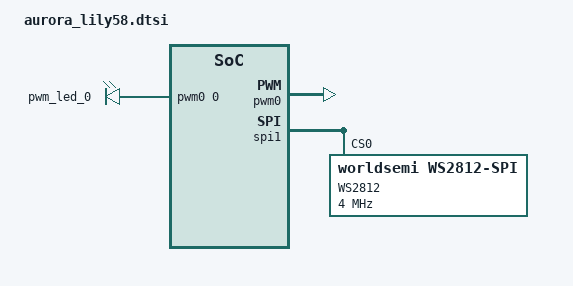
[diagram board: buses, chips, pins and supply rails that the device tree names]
/ {
    chosen {
        zmk,backlight,underglow = &backlight;
    };
};

&pwm0 {
    status = "okay";
};

&backlight {
    compatible = "pwm-leds";
    pwm_led_0 {
        pwms = <&pwm0 0 PWM_MSEC(20) PWM_POLARITY_NORMAL>;
    };
};

&spi1 {
    led_strip: ws2812@0 {
        compatible = "worldsemi,ws2812-spi";
        label = "WS2812";

        /* SPI */
        reg = <0>;
        spi-max-frequency = <4000000>;

        /* WS2812 */
        chain-length = <10>; /* number of LEDs */
        spi-one-frame = <0x70>;
        spi-zero-frame = <0x40>;
        color-mapping = <LED_COLOR_ID_GREEN LED_COLOR_ID_RED LED_COLOR_ID_BLUE>;
    };
};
